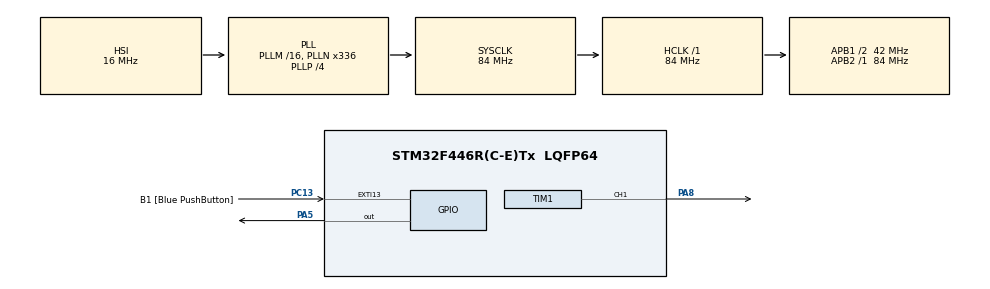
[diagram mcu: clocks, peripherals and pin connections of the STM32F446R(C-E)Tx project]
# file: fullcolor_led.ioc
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Dma.Request0=TIM1_CH1
Dma.TIM1_CH1.0.Direction=DMA_MEMORY_TO_PERIPH
Dma.TIM1_CH1.0.FIFOMode=DMA_FIFOMODE_DISABLE
Dma.TIM1_CH1.0.Instance=DMA2_Stream1
Dma.TIM1_CH1.0.MemDataAlignment=DMA_MDATAALIGN_WORD
Dma.TIM1_CH1.0.MemInc=DMA_MINC_ENABLE
Dma.TIM1_CH1.0.Mode=DMA_NORMAL
Dma.TIM1_CH1.0.PeriphDataAlignment=DMA_PDATAALIGN_WORD
Dma.TIM1_CH1.0.PeriphInc=DMA_PINC_DISABLE
Dma.TIM1_CH1.0.Priority=DMA_PRIORITY_HIGH
Mcu.Family=STM32F4
Mcu.Name=STM32F446R(C-E)Tx
Mcu.Package=LQFP64
NUCLEO-F446RE.LD1=true
NVIC.DMA2_Stream1_IRQn=true\:0\:0\:false\:false\:true\:false\:true\:true
NVIC.PriorityGroup=NVIC_PRIORITYGROUP_0
PA13.GPIO_Label=TMS
PA13.Signal=SYS_JTMS-SWDIO
PA14.GPIO_Label=TCK
PA14.Signal=SYS_JTCK-SWCLK
PA2.GPIO_Label=USART_TX
PA2.Signal=USART2_TX
PA3.GPIO_Label=USART_RX
PA3.Signal=USART2_RX
PA5.Signal=GPIO_Output
PA8.Signal=S_TIM1_CH1
PB3.GPIO_Label=SWO
PB3.Signal=SYS_JTDO-SWO
PC13.GPIO_Label=B1 [Blue PushButton]
PC13.GPIO_ModeDefaultEXTI=GPIO_MODE_IT_FALLING
PC13.Signal=GPXTI13
PC14-OSC32_IN.Signal=RCC_OSC32_IN
PC15-OSC32_OUT.Signal=RCC_OSC32_OUT
PH0-OSC_IN.Signal=RCC_OSC_IN
PH1-OSC_OUT.Signal=RCC_OSC_OUT
ProjectManager.HeapSize=0x200
ProjectManager.StackSize=0x400
ProjectManager.TargetToolchain=STM32CubeIDE
RCC.AHBFreq_Value=84000000
RCC.APB1CLKDivider=RCC_HCLK_DIV2
RCC.APB1Freq_Value=42000000
RCC.APB1TimFreq_Value=84000000
RCC.APB2Freq_Value=84000000
RCC.APB2TimFreq_Value=84000000
RCC.CortexFreq_Value=84000000
RCC.FLatency-AdvancedSettings=FLASH_LATENCY_2
RCC.HCLKFreq_Value=84000000
RCC.HSE_VALUE=8000000
RCC.HSI_VALUE=16000000
RCC.LSE_VALUE=32768
RCC.PLLN=336
RCC.PLLP=RCC_PLLP_DIV4
RCC.SYSCLKFreq_VALUE=84000000
RCC.SYSCLKSource=RCC_SYSCLKSOURCE_PLLCLK
RCC.USBFreq_Value=168000000
RCC.VCOOutputFreq_Value=336000000
SH.S_TIM1_CH1.0=TIM1_CH1,PWM Generation1 CH1
TIM1.Channel-PWM\ Generation1\ CH1=TIM_CHANNEL_1
TIM1.Period=104
VP_NUCLEO-F446RE_VS_BSP_COMMON.Mode=COMMON
board=NUCLEO-F446RE

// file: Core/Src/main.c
/* USER CODE BEGIN Header */
/**
  ******************************************************************************
  * @file           : main.c
  * @brief          : Main program body
  ******************************************************************************
  * @attention
  *
  * Copyright (c) 2026 STMicroelectronics.
  * All rights reserved.
  *
  * This software is licensed under terms that can be found in the LICENSE file
  * in the root directory of this software component.
  * If no LICENSE file comes with this software, it is provided AS-IS.
  *
  ******************************************************************************
  */
/* USER CODE END Header */
#include "main.h"

/* USER CODE BEGIN Includes */
#include "led.h"
/* USER CODE END Includes */

TIM_HandleTypeDef htim1;
DMA_HandleTypeDef hdma_tim1_ch1;

/* USER CODE BEGIN PV */
// Framebuffer: Array of LED structures directly managed by main.c
static LED strip[LED_COUNT];

static int16_t bullet_pos = -1;
static uint32_t last_led_tick = 0;
static uint32_t last_heartbeat_tick = 0;
static uint8_t prev_btn_state = GPIO_PIN_SET;
/* USER CODE END PV */

void SystemClock_Config(void);
static void MX_GPIO_Init(void);
static void MX_DMA_Init(void);
static void MX_TIM1_Init(void);

int main(void)
{

  /* MCU Configuration--------------------------------------------------------*/

  /* Reset of all peripherals, Initializes the Flash interface and the Systick. */
  HAL_Init();

  /* Configure the system clock */
  SystemClock_Config();

  /* Initialize all configured peripherals */
  MX_GPIO_Init();
  MX_DMA_Init();
  MX_TIM1_Init();
  /* USER CODE BEGIN 2 */
    LED_Init(&htim1, TIM_CHANNEL_1);
    for (uint16_t i = 0; i < LED_COUNT; i++) {
      strip[i].brightness = 80; // Safety brightness
    }
    uint8_t mode = 0; // Mode index (0 to 6)
    /* USER CODE END 2 */

    /* Infinite loop */
    /* USER CODE BEGIN WHILE */
    while (1)
    {
      uint32_t now = HAL_GetTick();

      // 1. Button click detection: Cycle through animation modes
      uint8_t current_btn = HAL_GPIO_ReadPin(B1_GPIO_Port, B1_Pin);
      if (prev_btn_state == GPIO_PIN_SET && current_btn == GPIO_PIN_RESET)
      {
        mode = (mode + 1) % 7;
        bullet_pos = 0; // Reset tracer trigger if applicable
      }
      prev_btn_state = current_btn;

      // 2. LED Frame Rendering (runs every 15ms)
      if (now - last_led_tick >= 15)
      {
        last_led_tick = now;

        switch (mode) {
          case 0:
            LED_Anim_Rainbow(strip, LED_COUNT, 1);
            break;
          case 1:
            LED_Anim_ShootingStar(strip, LED_COUNT, &bullet_pos, 0, 200, 255);
            if (bullet_pos < 0) bullet_pos = 0; // Auto loop firing
            break;
          case 2:
            LED_Anim_Scanner(strip, LED_COUNT, 255, 0, 0); // Red Cylon scanner
            break;
          case 3:
            LED_Anim_Breathing(strip, LED_COUNT, 0, 100, 255); // Cyan reactor breathing
            break;
          case 4:
            LED_Anim_ColorWipe(strip, LED_COUNT, 0, 255, 100); // Green reload bar
            break;
          case 5:
            LED_Anim_Sparkle(strip, LED_COUNT, 255, 255, 255, 2); // White sparks
            break;
          case 6:
            LED_Anim_Fire(strip, LED_COUNT); // Burning plasma flame
            break;
        }
        LED_Show(strip, LED_COUNT);
      }

      // 3. Heartbeat
      if (now - last_heartbeat_tick >= 500)
      {
        last_heartbeat_tick = now;
        HAL_GPIO_TogglePin(GPIOA, GPIO_PIN_5);
      }
      /* USER CODE END WHILE */
  }
}

void SystemClock_Config(void)
{
  RCC_OscInitTypeDef RCC_OscInitStruct = {0};
  RCC_ClkInitTypeDef RCC_ClkInitStruct = {0};

  /** Configure the main internal regulator output voltage
  */
  __HAL_RCC_PWR_CLK_ENABLE();
  __HAL_PWR_VOLTAGESCALING_CONFIG(PWR_REGULATOR_VOLTAGE_SCALE3);

  /** Initializes the RCC Oscillators according to the specified parameters
  * in the RCC_OscInitTypeDef structure.
  */
  RCC_OscInitStruct.OscillatorType = RCC_OSCILLATORTYPE_HSI;
  RCC_OscInitStruct.HSIState = RCC_HSI_ON;
  RCC_OscInitStruct.HSICalibrationValue = RCC_HSICALIBRATION_DEFAULT;
  RCC_OscInitStruct.PLL.PLLState = RCC_PLL_ON;
  RCC_OscInitStruct.PLL.PLLSource = RCC_PLLSOURCE_HSI;
  RCC_OscInitStruct.PLL.PLLM = 16;
  RCC_OscInitStruct.PLL.PLLN = 336;
  RCC_OscInitStruct.PLL.PLLP = RCC_PLLP_DIV4;
  RCC_OscInitStruct.PLL.PLLQ = 2;
  RCC_OscInitStruct.PLL.PLLR = 2;
  if (HAL_RCC_OscConfig(&RCC_OscInitStruct) != HAL_OK)
  {
    Error_Handler();
  }

  /** Initializes the CPU, AHB and APB buses clocks
  */
  RCC_ClkInitStruct.ClockType = RCC_CLOCKTYPE_HCLK|RCC_CLOCKTYPE_SYSCLK
                              |RCC_CLOCKTYPE_PCLK1|RCC_CLOCKTYPE_PCLK2;
  RCC_ClkInitStruct.SYSCLKSource = RCC_SYSCLKSOURCE_PLLCLK;
  RCC_ClkInitStruct.AHBCLKDivider = RCC_SYSCLK_DIV1;
  RCC_ClkInitStruct.APB1CLKDivider = RCC_HCLK_DIV2;
  RCC_ClkInitStruct.APB2CLKDivider = RCC_HCLK_DIV1;

  if (HAL_RCC_ClockConfig(&RCC_ClkInitStruct, FLASH_LATENCY_2) != HAL_OK)
  {
    Error_Handler();
  }
}

static void MX_TIM1_Init(void)
{

  TIM_MasterConfigTypeDef sMasterConfig = {0};
  TIM_OC_InitTypeDef sConfigOC = {0};
  TIM_BreakDeadTimeConfigTypeDef sBreakDeadTimeConfig = {0};

  htim1.Instance = TIM1;
  htim1.Init.Prescaler = 0;
  htim1.Init.CounterMode = TIM_COUNTERMODE_UP;
  htim1.Init.Period = 104;
  htim1.Init.ClockDivision = TIM_CLOCKDIVISION_DIV1;
  htim1.Init.RepetitionCounter = 0;
  htim1.Init.AutoReloadPreload = TIM_AUTORELOAD_PRELOAD_DISABLE;
  if (HAL_TIM_PWM_Init(&htim1) != HAL_OK)
  {
    Error_Handler();
  }
  sMasterConfig.MasterOutputTrigger = TIM_TRGO_RESET;
  sMasterConfig.MasterSlaveMode = TIM_MASTERSLAVEMODE_DISABLE;
  if (HAL_TIMEx_MasterConfigSynchronization(&htim1, &sMasterConfig) != HAL_OK)
  {
    Error_Handler();
  }
  sConfigOC.OCMode = TIM_OCMODE_PWM1;
  sConfigOC.Pulse = 0;
  sConfigOC.OCPolarity = TIM_OCPOLARITY_HIGH;
  sConfigOC.OCNPolarity = TIM_OCNPOLARITY_HIGH;
  sConfigOC.OCFastMode = TIM_OCFAST_DISABLE;
  sConfigOC.OCIdleState = TIM_OCIDLESTATE_RESET;
  sConfigOC.OCNIdleState = TIM_OCNIDLESTATE_RESET;
  if (HAL_TIM_PWM_ConfigChannel(&htim1, &sConfigOC, TIM_CHANNEL_1) != HAL_OK)
  {
    Error_Handler();
  }
  sBreakDeadTimeConfig.OffStateRunMode = TIM_OSSR_DISABLE;
  sBreakDeadTimeConfig.OffStateIDLEMode = TIM_OSSI_DISABLE;
  sBreakDeadTimeConfig.LockLevel = TIM_LOCKLEVEL_OFF;
  sBreakDeadTimeConfig.DeadTime = 0;
  sBreakDeadTimeConfig.BreakState = TIM_BREAK_DISABLE;
  sBreakDeadTimeConfig.BreakPolarity = TIM_BREAKPOLARITY_HIGH;
  sBreakDeadTimeConfig.AutomaticOutput = TIM_AUTOMATICOUTPUT_DISABLE;
  if (HAL_TIMEx_ConfigBreakDeadTime(&htim1, &sBreakDeadTimeConfig) != HAL_OK)
  {
    Error_Handler();
  }
  HAL_TIM_MspPostInit(&htim1);

}

static void MX_DMA_Init(void)
{

  /* DMA controller clock enable */
  __HAL_RCC_DMA2_CLK_ENABLE();

  /* DMA interrupt init */
  /* DMA2_Stream1_IRQn interrupt configuration */
  HAL_NVIC_SetPriority(DMA2_Stream1_IRQn, 0, 0);
  HAL_NVIC_EnableIRQ(DMA2_Stream1_IRQn);

}

static void MX_GPIO_Init(void)
{
  GPIO_InitTypeDef GPIO_InitStruct = {0};

  /* GPIO Ports Clock Enable */
  __HAL_RCC_GPIOC_CLK_ENABLE();
  __HAL_RCC_GPIOH_CLK_ENABLE();
  __HAL_RCC_GPIOA_CLK_ENABLE();
  __HAL_RCC_GPIOB_CLK_ENABLE();

  /*Configure GPIO pin : B1_Pin */
  GPIO_InitStruct.Pin = B1_Pin;
  GPIO_InitStruct.Mode = GPIO_MODE_IT_FALLING;
  GPIO_InitStruct.Pull = GPIO_NOPULL;
  HAL_GPIO_Init(B1_GPIO_Port, &GPIO_InitStruct);

  /*Configure GPIO pins : USART_TX_Pin USART_RX_Pin */
  GPIO_InitStruct.Pin = USART_TX_Pin|USART_RX_Pin;
  GPIO_InitStruct.Mode = GPIO_MODE_AF_PP;
  GPIO_InitStruct.Pull = GPIO_NOPULL;
  GPIO_InitStruct.Speed = GPIO_SPEED_FREQ_VERY_HIGH;
  GPIO_InitStruct.Alternate = GPIO_AF7_USART2;
  HAL_GPIO_Init(GPIOA, &GPIO_InitStruct);

}

void Error_Handler(void)
{
  __disable_irq();
  while (1)
  {
  }
}
